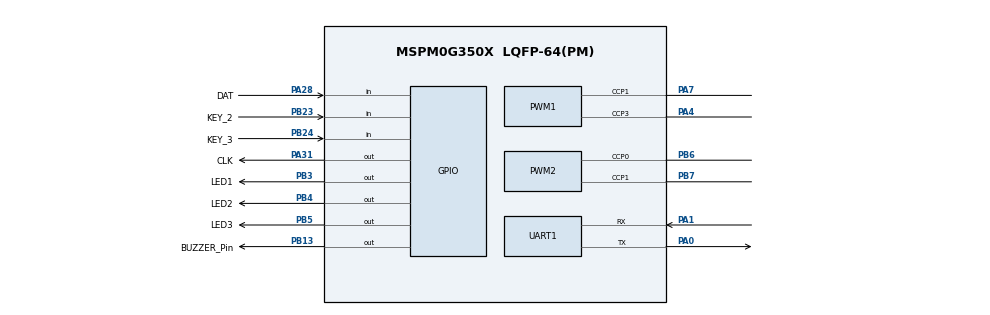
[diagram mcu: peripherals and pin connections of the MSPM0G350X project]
/**
 * @cliArgs --device "MSPM0G350X" --part "Default" --package "LQFP-64(PM)" --product "mspm0_sdk@2.02.00.05"
 * @versions {"tool":"1.21.1+3772"}
 */

/**
 * Import the modules used in this configuration.
 */
const GPIO    = scripting.addModule("/ti/driverlib/GPIO", {}, false);
const GPIO1   = GPIO.addInstance();
const GPIO2   = GPIO.addInstance();
const GPIO3   = GPIO.addInstance();
const GPIO4   = GPIO.addInstance();
const GPIO5   = GPIO.addInstance();
const GPIO6   = GPIO.addInstance();
const GPIO7   = GPIO.addInstance();
const GPIO8   = GPIO.addInstance();
const GPIO9   = GPIO.addInstance();
const GPIO10  = GPIO.addInstance();
const GPIO11  = GPIO.addInstance();
const PWM     = scripting.addModule("/ti/driverlib/PWM", {}, false);
const PWM1    = PWM.addInstance();
const PWM2    = PWM.addInstance();
const SYSCTL  = scripting.addModule("/ti/driverlib/SYSCTL");
const SYSTICK = scripting.addModule("/ti/driverlib/SYSTICK");
const TIMER   = scripting.addModule("/ti/driverlib/TIMER", {}, false);
const TIMER1  = TIMER.addInstance();
const UART    = scripting.addModule("/ti/driverlib/UART", {}, false);
const UART1   = UART.addInstance();

/**
 * Write custom configuration values to the imported modules.
 */
const divider9       = system.clockTree["UDIV"];
divider9.divideValue = 2;

const gate7  = system.clockTree["MFCLKGATE"];
gate7.enable = true;

const multiplier2         = system.clockTree["PLL_QDIV"];
multiplier2.multiplyValue = 20;

const mux4       = system.clockTree["EXHFMUX"];
mux4.inputSelect = "EXHFMUX_XTAL";

const mux8       = system.clockTree["HSCLKMUX"];
mux8.inputSelect = "HSCLKMUX_SYSPLL0";

const mux12       = system.clockTree["SYSPLLMUX"];
mux12.inputSelect = "zSYSPLLMUX_HFCLK";

const pinFunction4     = system.clockTree["HFXT"];
pinFunction4.inputFreq = 8;
pinFunction4.enable    = true;

GPIO1.$name                              = "KEY";
GPIO1.port                               = "PORTB";
GPIO1.associatedPins.create(3);
GPIO1.associatedPins[0].direction        = "INPUT";
GPIO1.associatedPins[0].$name            = "KEY_1";
GPIO1.associatedPins[0].internalResistor = "PULL_UP";
GPIO1.associatedPins[0].assignedPin      = "21";
GPIO1.associatedPins[1].direction        = "INPUT";
GPIO1.associatedPins[1].assignedPin      = "23";
GPIO1.associatedPins[1].$name            = "KEY_2";
GPIO1.associatedPins[1].internalResistor = "PULL_UP";
GPIO1.associatedPins[1].pin.$assign      = "PB23";
GPIO1.associatedPins[2].$name            = "KEY_3";
GPIO1.associatedPins[2].direction        = "INPUT";
GPIO1.associatedPins[2].pin.$assign      = "PB24";

const Board = scripting.addModule("/ti/driverlib/Board", {}, false);

GPIO2.$name                          = "TB6612";
GPIO2.associatedPins.create(4);
GPIO2.associatedPins[0].$name        = "AIN1";
GPIO2.associatedPins[0].assignedPort = "PORTB";
GPIO2.associatedPins[0].assignedPin  = "17";
GPIO2.associatedPins[1].$name        = "AIN2";
GPIO2.associatedPins[1].assignedPort = "PORTB";
GPIO2.associatedPins[1].assignedPin  = "18";
GPIO2.associatedPins[2].$name        = "BIN1";
GPIO2.associatedPins[2].assignedPort = "PORTB";
GPIO2.associatedPins[2].assignedPin  = "19";
GPIO2.associatedPins[3].$name        = "BIN2";
GPIO2.associatedPins[3].assignedPort = "PORTB";
GPIO2.associatedPins[3].assignedPin  = "20";

GPIO3.$name                          = "OLED";
GPIO3.associatedPins.create(2);
GPIO3.associatedPins[0].$name        = "SCL";
GPIO3.associatedPins[0].initialValue = "SET";
GPIO3.associatedPins[0].assignedPort = "PORTA";
GPIO3.associatedPins[0].assignedPin  = "17";
GPIO3.associatedPins[1].$name        = "SDA";
GPIO3.associatedPins[1].initialValue = "SET";
GPIO3.associatedPins[1].assignedPort = "PORTB";
GPIO3.associatedPins[1].assignedPin  = "15";

GPIO4.$name                          = "TRACK";
GPIO4.port                           = "PORTA";
GPIO4.associatedPins.create(2);
GPIO4.associatedPins[0].$name        = "CLK";
GPIO4.associatedPins[0].initialValue = "SET";
GPIO4.associatedPins[0].pin.$assign  = "PA31";
GPIO4.associatedPins[1].$name        = "DAT";
GPIO4.associatedPins[1].initialValue = "SET";
GPIO4.associatedPins[1].direction    = "INPUT";
GPIO4.associatedPins[1].pin.$assign  = "PA28";

GPIO5.$name                          = "BUZZER";
GPIO5.port                           = "PORTB";
GPIO5.associatedPins[0].$name        = "BUZZER_Pin";
GPIO5.associatedPins[0].initialValue = "SET";
GPIO5.associatedPins[0].assignedPin  = "13";
GPIO5.associatedPins[0].pin.$assign  = "PB13";

GPIO6.$name                         = "LED";
GPIO6.associatedPins.create(3);
GPIO6.associatedPins[0].$name       = "LED1";
GPIO6.associatedPins[0].pin.$assign = "PB3";
GPIO6.associatedPins[1].$name       = "LED2";
GPIO6.associatedPins[1].pin.$assign = "PB4";
GPIO6.associatedPins[2].$name       = "LED3";
GPIO6.associatedPins[2].pin.$assign = "PB5";

GPIO7.$name                         = "L2";
GPIO7.port                          = "PORTB";
GPIO7.associatedPins[0].$name       = "PIN_L2";
GPIO7.associatedPins[0].direction   = "INPUT";
GPIO7.associatedPins[0].assignedPin = "8";

GPIO8.$name                         = "L1";
GPIO8.port                          = "PORTB";
GPIO8.associatedPins[0].$name       = "PIN_L1";
GPIO8.associatedPins[0].direction   = "INPUT";
GPIO8.associatedPins[0].assignedPin = "9";

GPIO9.$name                         = "M0";
GPIO9.port                          = "PORTB";
GPIO9.associatedPins[0].$name       = "PIN_M0";
GPIO9.associatedPins[0].direction   = "INPUT";
GPIO9.associatedPins[0].assignedPin = "10";

GPIO10.$name                          = "R1";
GPIO10.associatedPins[0].$name        = "PIN_R1";
GPIO10.associatedPins[0].direction    = "INPUT";
GPIO10.associatedPins[0].assignedPort = "PORTB";
GPIO10.associatedPins[0].assignedPin  = "11";

GPIO11.$name                         = "R2";
GPIO11.port                          = "PORTB";
GPIO11.associatedPins[0].$name       = "PIN_R2";
GPIO11.associatedPins[0].direction   = "INPUT";
GPIO11.associatedPins[0].assignedPin = "12";

PWM1.$name                      = "PWM_0";
PWM1.clockDivider               = 8;
PWM1.timerCount                 = 100;
PWM1.clockPrescale              = 2;
PWM1.timerStartTimer            = true;
PWM1.pwmMode                    = "EDGE_ALIGN_UP";
PWM1.ccIndex                    = [1,3];
PWM1.peripheral.$assign         = "TIMA0";
PWM1.peripheral.ccp1Pin.$assign = "PA7";
PWM1.peripheral.ccp3Pin.$assign = "PA4";
PWM1.ccp1PinConfig.$name        = "ti_driverlib_gpio_GPIOPinGeneric8";
PWM1.PWM_CHANNEL_3.$name        = "ti_driverlib_pwm_PWMTimerCC5";
PWM1.ccp3PinConfig.$name        = "ti_driverlib_gpio_GPIOPinGeneric5";
PWM1.PWM_CHANNEL_1.$name        = "ti_driverlib_pwm_PWMTimerCC0";

PWM2.$name                              = "PWM_steer";
PWM2.clockDivider                       = 8;
PWM2.timerStartTimer                    = true;
PWM2.clockPrescale                      = 80;
PWM2.peripheral.ccp0Pin.$assign         = "PB6";
PWM2.peripheral.ccp1Pin.$assign         = "PB7";
PWM2.PWM_CHANNEL_0.$name                = "ti_driverlib_pwm_PWMTimerCC2";
PWM2.PWM_CHANNEL_1.$name                = "ti_driverlib_pwm_PWMTimerCC3";
PWM2.ccp0PinConfig.$name                = "ti_driverlib_gpio_GPIOPinGeneric2";
PWM2.ccp0PinConfig.direction            = scripting.forceWrite("OUTPUT");
PWM2.ccp0PinConfig.hideOutputInversion  = scripting.forceWrite(false);
PWM2.ccp0PinConfig.onlyInternalResistor = scripting.forceWrite(false);
PWM2.ccp0PinConfig.passedPeripheralType = scripting.forceWrite("Digital");
PWM2.ccp1PinConfig.$name                = "ti_driverlib_gpio_GPIOPinGeneric3";
PWM2.ccp1PinConfig.direction            = scripting.forceWrite("OUTPUT");
PWM2.ccp1PinConfig.hideOutputInversion  = scripting.forceWrite(false);
PWM2.ccp1PinConfig.onlyInternalResistor = scripting.forceWrite(false);
PWM2.ccp1PinConfig.passedPeripheralType = scripting.forceWrite("Digital");

SYSCTL.forceDefaultClkConfig = true;
SYSCTL.clockTreeEn           = true;

SYSTICK.periodEnable      = true;
SYSTICK.period            = 32000;
SYSTICK.interruptEnable   = true;
SYSTICK.interruptPriority = "0";
SYSTICK.systickEnable     = true;

TIMER1.$name            = "TIMER_0";
TIMER1.timerClkDiv      = 8;
TIMER1.timerClkPrescale = 100;
TIMER1.timerMode        = "PERIODIC_UP";
TIMER1.timerStartTimer  = true;
TIMER1.interrupts       = ["LOAD"];
TIMER1.timerPeriod      = "1ms";

UART1.$name                    = "UART_0";
UART1.uartClkSrc               = "MFCLK";
UART1.enabledInterrupts        = ["RX"];
UART1.peripheral.$assign       = "UART0";
UART1.peripheral.rxPin.$assign = "PA1";
UART1.peripheral.txPin.$assign = "PA0";
UART1.txPinConfig.$name        = "ti_driverlib_gpio_GPIOPinGeneric0";
UART1.rxPinConfig.$name        = "ti_driverlib_gpio_GPIOPinGeneric1";

/**
 * Pinmux solution for unlocked pins/peripherals. This ensures that minor changes to the automatic solver in a future
 * version of the tool will not impact the pinmux you originally saw.  These lines can be completely deleted in order to
 * re-solve from scratch.
 */
pinFunction4.peripheral.$suggestSolution           = "SYSCTL";
pinFunction4.peripheral.hfxInPin.$suggestSolution  = "PA5";
pinFunction4.peripheral.hfxOutPin.$suggestSolution = "PA6";
GPIO1.associatedPins[0].pin.$suggestSolution       = "PB21";
Board.peripheral.$suggestSolution                  = "DEBUGSS";
Board.peripheral.swclkPin.$suggestSolution         = "PA20";
Board.peripheral.swdioPin.$suggestSolution         = "PA19";
GPIO2.associatedPins[0].pin.$suggestSolution       = "PB17";
GPIO2.associatedPins[1].pin.$suggestSolution       = "PB18";
GPIO2.associatedPins[2].pin.$suggestSolution       = "PB19";
GPIO2.associatedPins[3].pin.$suggestSolution       = "PB20";
GPIO3.associatedPins[0].pin.$suggestSolution       = "PA17";
GPIO3.associatedPins[1].pin.$suggestSolution       = "PB15";
GPIO7.associatedPins[0].pin.$suggestSolution       = "PB8";
GPIO8.associatedPins[0].pin.$suggestSolution       = "PB9";
GPIO9.associatedPins[0].pin.$suggestSolution       = "PB10";
GPIO10.associatedPins[0].pin.$suggestSolution      = "PB11";
GPIO11.associatedPins[0].pin.$suggestSolution      = "PB12";
PWM2.peripheral.$suggestSolution                   = "TIMG6";
TIMER1.peripheral.$suggestSolution                 = "TIMA1";
